# ATSAM4E16E register map
Vendor: Atmel; Series: SAM4E; File version: 0
CPU: CM4 r0p0, selectable endian, MPU, FPU, 4 interrupt priority bits
Registers are 32-bit, read-write, reset 0x0 unless marked. A register's access mark holds for its fields unless they carry their own. Offsets are from the block's base; [hi:lo] are bit positions.

## UART1 — Universal Asynchronous Receiver Transmitter 1
Base 0x40060600; register names take the prefix UART1_
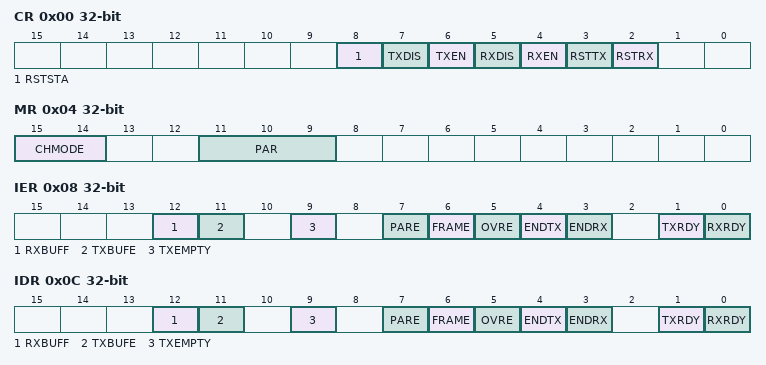
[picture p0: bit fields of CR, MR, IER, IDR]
0x00 CR wo reset not defined — Control Register
  [8] RSTSTA — Reset Status Bits
  [7] TXDIS — Transmitter Disable
  [6] TXEN — Transmitter Enable
  [5] RXDIS — Receiver Disable
  [4] RXEN — Receiver Enable
  [3] RSTTX — Reset Transmitter
  [2] RSTRX — Reset Receiver
0x04 MR — Mode Register
  [15:14] CHMODE — Channel Mode
    0=NORMAL (Normal Mode); 1=AUTOMATIC (Automatic Echo); 2=LOCAL_LOOPBACK; 3=REMOTE_LOOPBACK
  [11:9] PAR — Parity Type
    0=EVEN (Even Parity); 1=ODD (Odd Parity); 2=SPACE (Space: parity forced to 0); 3=MARK (Mark: parity forced to 1); 4=NO (No Parity)
0x08 IER wo reset not defined — Interrupt Enable Register
  [12] RXBUFF — Receive Buffer Full Interrupt Enable
  [11] TXBUFE — Enable Buffer Empty Interrupt
  [9] TXEMPTY — TXEMPTY Interrupt Enable
  [7] PARE — Parity Error Interrupt Enable
  [6] FRAME — Framing Error Interrupt Enable
  [5] OVRE — Overrun Error Interrupt Enable
  [4] ENDTX — End of Transmit Buffer Interrupt Enable (available in all USART modes of operation)
  [3] ENDRX — End of Receive Buffer Interrupt Enable (available in all USART modes of operation)
  [1] TXRDY — TXRDY Interrupt Enable
  [0] RXRDY — RXRDY Interrupt Enable
0x0C IDR wo reset not defined — Interrupt Disable Register
  [12] RXBUFF — Receive Buffer Full Interrupt Disable
  [11] TXBUFE — Disable Buffer Empty Interrupt
  [9] TXEMPTY — TXEMPTY Interrupt Disable
  [7] PARE — Parity Error Interrupt Disable
  [6] FRAME — Framing Error Interrupt Disable
  [5] OVRE — Overrun Error Interrupt Enable
  [4] ENDTX — End of Transmit Buffer Interrupt Disable (available in all USART modes of operation)
  [3] ENDRX — End of Receive Buffer Transfer Interrupt Disable (available in all USART modes of operation)
  [1] TXRDY — TXRDY Interrupt Disable
  [0] RXRDY — RXRDY Interrupt Disable
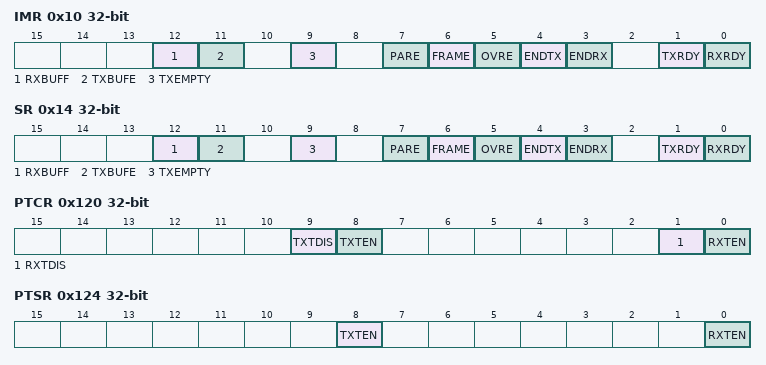
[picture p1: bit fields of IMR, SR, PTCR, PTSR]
0x10 IMR ro — Interrupt Mask Register
  [12] RXBUFF — Receive Buffer Full Interrupt Mask
  [11] TXBUFE — Mask TXBUFE Interrupt
  [9] TXEMPTY — TXEMPTY Interrupt Mask
  [7] PARE — Parity Error Interrupt Mask
  [6] FRAME — Framing Error Interrupt Mask
  [5] OVRE — Overrun Error Interrupt Mask
  [4] ENDTX — End of Transmit Buffer Interrupt Mask (available in all USART modes of operation)
  [3] ENDRX — End of Receive Buffer Interrupt Mask (available in all USART modes of operation)
  [1] TXRDY — TXRDY Interrupt Mask
  [0] RXRDY — RXRDY Interrupt Mask
0x14 SR ro reset not defined — Status Register
  [12] RXBUFF — Receive Buffer Full
  [11] TXBUFE — Transmission Buffer Empty
  [9] TXEMPTY — Transmitter Empty
  [7] PARE — Parity Error
  [6] FRAME — Framing Error
  [5] OVRE — Overrun Error
  [4] ENDTX — End of Transmitter Transfer
  [3] ENDRX — End of Receiver Transfer
  [1] TXRDY — Transmitter Ready
  [0] RXRDY — Receiver Ready
0x18 RHR ro — Receive Holding Register
  [7:0] RXCHR — Received Character
0x1C THR wo reset not defined — Transmit Holding Register
  [7:0] TXCHR — Character to be Transmitted
0x20 BRGR — Baud Rate Generator Register
  [15:0] CD — Clock Divider
0x100 RPR — Receive Pointer Register
  [31:0] RXPTR
0x104 RCR — Receive Counter Register
  [15:0] RXCTR
0x108 TPR — Transmit Pointer Register
  [31:0] TXPTR — Transmit Counter Register
0x10C TCR — Transmit Counter Register
  [15:0] TXCTR
0x110 RNPR — Receive Next Pointer Register
  [31:0] RXNPTR — Receive Next Pointer
0x114 RNCR — Receive Next Counter Register
  [15:0] RXNCTR — Receive Next Counter
0x118 TNPR — Transmit Next Pointer Register
  [31:0] TXNPTR — Transmit Next Pointer
0x11C TNCR — Transmit Next Counter Register
  [15:0] TXNCTR — Transmit Counter Next
0x120 PTCR wo reset not defined — Transfer Control Register
  [9] TXTDIS — Transmitter Transfer Disable
  [8] TXTEN — Transmitter Transfer Enable
  [1] RXTDIS — Receiver Transfer Disable
  [0] RXTEN — Receiver Transfer Enable
0x124 PTSR ro — Transfer Status Register
  [8] TXTEN — Transmitter Transfer Enable
  [0] RXTEN — Receiver Transfer Enable

## UART0 — Universal Asynchronous Receiver Transmitter 0
Base 0x400E0600; register names take the prefix UART0_
Registers as UART1; these are added or differ:
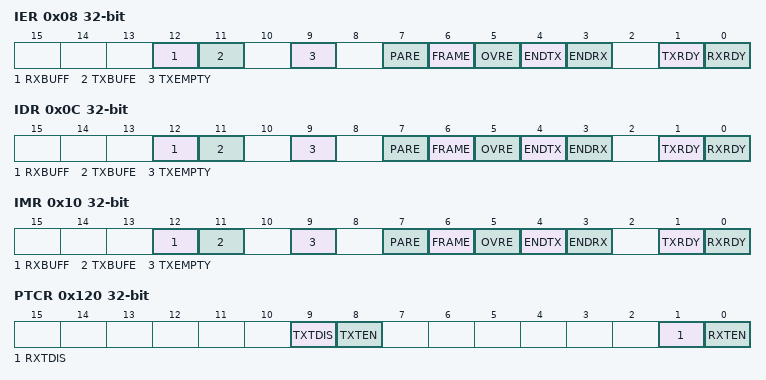
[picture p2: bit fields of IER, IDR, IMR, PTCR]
0x08 IER wo reset not defined — Interrupt Enable Register
  [12] RXBUFF — Enable Buffer Full Interrupt
  [11] TXBUFE — Enable Buffer Empty Interrupt
  [9] TXEMPTY — Enable TXEMPTY Interrupt
  [7] PARE — Enable Parity Error Interrupt
  [6] FRAME — Enable Framing Error Interrupt
  [5] OVRE — Enable Overrun Error Interrupt
  [4] ENDTX — Enable End of Transmit Interrupt
  [3] ENDRX — Enable End of Receive Transfer Interrupt
  [1] TXRDY — Enable TXRDY Interrupt
  [0] RXRDY — Enable RXRDY Interrupt
0x0C IDR wo reset not defined — Interrupt Disable Register
  [12] RXBUFF — Disable Buffer Full Interrupt
  [11] TXBUFE — Disable Buffer Empty Interrupt
  [9] TXEMPTY — Disable TXEMPTY Interrupt
  [7] PARE — Disable Parity Error Interrupt
  [6] FRAME — Disable Framing Error Interrupt
  [5] OVRE — Disable Overrun Error Interrupt
  [4] ENDTX — Disable End of Transmit Interrupt
  [3] ENDRX — Disable End of Receive Transfer Interrupt
  [1] TXRDY — Disable TXRDY Interrupt
  [0] RXRDY — Disable RXRDY Interrupt
0x10 IMR ro — Interrupt Mask Register
  [12] RXBUFF — Mask RXBUFF Interrupt
  [11] TXBUFE — Mask TXBUFE Interrupt
  [9] TXEMPTY — Mask TXEMPTY Interrupt
  [7] PARE — Mask Parity Error Interrupt
  [6] FRAME — Mask Framing Error Interrupt
  [5] OVRE — Mask Overrun Error Interrupt
  [4] ENDTX — Mask End of Transmit Interrupt
  [3] ENDRX — Mask End of Receive Transfer Interrupt
  [1] TXRDY — Disable TXRDY Interrupt
  [0] RXRDY — Mask RXRDY Interrupt
0x20 BRGR — Baud Rate Generator Register
  [15:0] CD — Clock Divisor
0x120 PTCR wo — Transfer Control Register
  [9] TXTDIS — Transmitter Transfer Disable
  [8] TXTEN — Transmitter Transfer Enable
  [1] RXTDIS — Receiver Transfer Disable
  [0] RXTEN — Receiver Transfer Enable

## Notices in the file
SAM Software Package License
Copyright (c) %copyright_year%, Atmel Corporation
All rights reserved.
Redistribution and use in source and binary forms, with or without
modification, are permitted provided that the following condition is met:
- Redistributions of source code must retain the above copyright notice,
this list of conditions and the disclaimer below.
Atmel's name may not be used to endorse or promote products derived from
this software without specific prior written permission.
DISCLAIMER:  THIS SOFTWARE IS PROVIDED BY ATMEL "AS IS" AND ANY EXPRESS OR
IMPLIED WARRANTIES, INCLUDING, BUT NOT LIMITED TO, THE IMPLIED WARRANTIES OF
MERCHANTABILITY, FITNESS FOR A PARTICULAR PURPOSE AND NON-INFRINGEMENT ARE
DISCLAIMED. IN NO EVENT SHALL ATMEL BE LIABLE FOR ANY DIRECT, INDIRECT,
INCIDENTAL, SPECIAL, EXEMPLARY, OR CONSEQUENTIAL DAMAGES (INCLUDING, BUT NOT
LIMITED TO, PROCUREMENT OF SUBSTITUTE GOODS OR SERVICES; LOSS OF USE, DATA,
OR PROFITS; OR BUSINESS INTERRUPTION) HOWEVER CAUSED AND ON ANY THEORY OF
LIABILITY, WHETHER IN CONTRACT, STRICT LIABILITY, OR TORT (INCLUDING
NEGLIGENCE OR OTHERWISE) ARISING IN ANY WAY OUT OF THE USE OF THIS SOFTWARE,
EVEN IF ADVISED OF THE POSSIBILITY OF SUCH DAMAGE.
